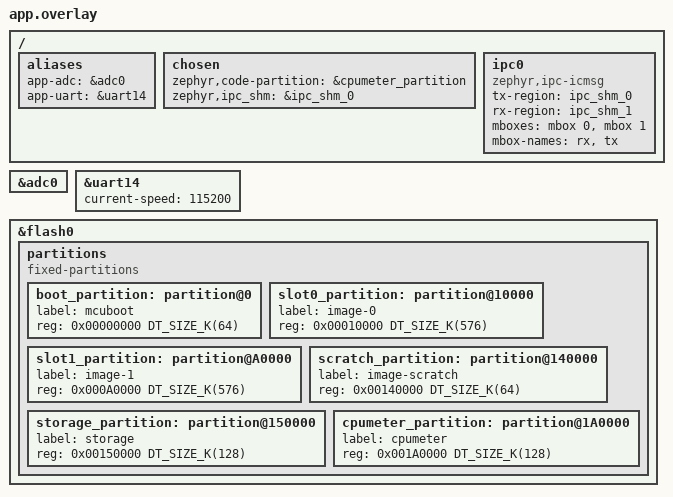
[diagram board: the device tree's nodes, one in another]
&adc0 { status = "okay"; };
&uart14 { status = "okay"; current-speed = <115200>; };

&flash0 {
    partitions {
        compatible = "fixed-partitions";
        #address-cells = <1>;
        #size-cells = <1>;

        boot_partition: partition@0 {
            label = "mcuboot";
            reg = <0x00000000 DT_SIZE_K(64)>;
        };
        slot0_partition: partition@10000 {
            label = "image-0";
            reg = <0x00010000 DT_SIZE_K(576)>; 
        };
        slot1_partition: partition@A0000 {
            label = "image-1";
            reg = <0x000A0000 DT_SIZE_K(576)>; 
        };
        scratch_partition: partition@140000 {
            label = "image-scratch";
            reg = <0x00140000 DT_SIZE_K(64)>;
        };
        storage_partition: partition@150000 {
            label = "storage";
            reg = <0x00150000 DT_SIZE_K(128)>;
        };
        cpumeter_partition: partition@1A0000 {
            label = "cpumeter";
            reg = <0x001A0000 DT_SIZE_K(128)>;
        };
    };
};

/ {
    aliases {
        app-adc = &adc0;
        app-uart = &uart14;
    };

    chosen {
        zephyr,code-partition = &cpumeter_partition;
        zephyr,ipc_shm = &ipc_shm_0;
    };

    ipc0: ipc0 {
        compatible = "zephyr,ipc-icmsg";
        tx-region = <&ipc_shm_0>;
        rx-region = <&ipc_shm_1>;
        mboxes = <&mbox 0>, <&mbox 1>;
        mbox-names = "rx", "tx";
        status = "okay";
    };
};
